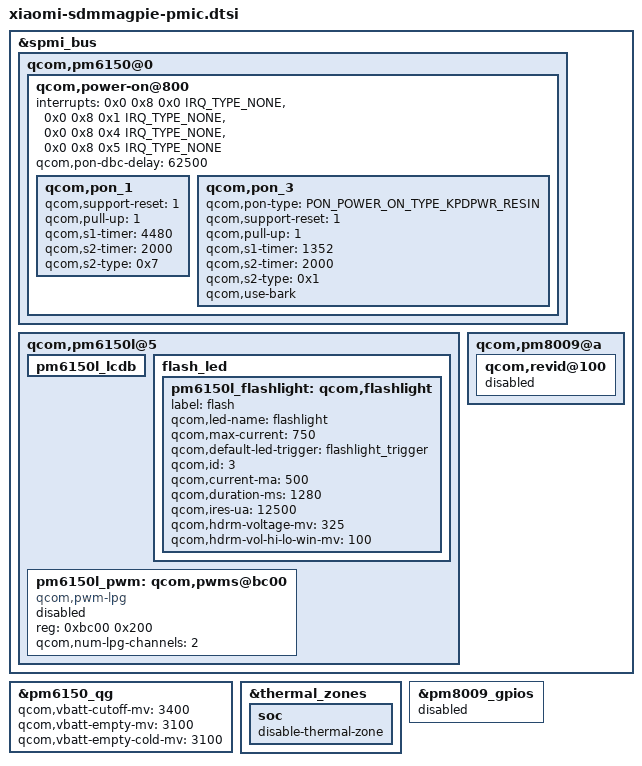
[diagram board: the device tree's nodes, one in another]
/*
 * Copyright (C) 2020 The LineageOS Project
 *
 */

#include <dt-bindings/input/input.h>
#include <dt-bindings/input/qcom,qpnp-power-on.h>
#include <dt-bindings/interrupt-controller/irq.h>
#include <dt-bindings/spmi/spmi.h>
#include <dt-bindings/iio/qcom,spmi-vadc.h>

&spmi_bus {
    qcom,pm6150@0 {
        qcom,power-on@800 {
            interrupts = <0x0 0x8 0x0 IRQ_TYPE_NONE>,
                   <0x0 0x8 0x1 IRQ_TYPE_NONE>,
                   <0x0 0x8 0x4 IRQ_TYPE_NONE>,
                   <0x0 0x8 0x5 IRQ_TYPE_NONE>;
            interrupt-names = "kpdpwr", "resin",
                    "resin-bark", "kpdpwr-resin-bark";
            qcom,pon-dbc-delay = <62500>;
            qcom,pon_1 {
                qcom,support-reset = <1>;
                qcom,pull-up = <1>;
                qcom,s1-timer = <4480>;
                qcom,s2-timer = <2000>;
                qcom,s2-type = <0x7>;
            };
            qcom,pon_3 {
                qcom,pon-type = <PON_POWER_ON_TYPE_KPDPWR_RESIN>;
                qcom,support-reset = <1>;
                qcom,pull-up = <1>;
                qcom,s1-timer = <1352>;
                qcom,s2-timer = <2000>;
                qcom,s2-type = <0x1>;
                qcom,use-bark;
            };
        };
    };
    qcom,pm6150l@5 {
        /delete-node/ pm6150l_pwm_1;
        pm6150l_lcdb {
            /delete-property/ qcom,voltage-step-ramp;
        };
        flash_led {
            pm6150l_flashlight: qcom,flashlight {
                label = "flash";
                qcom,led-name = "flashlight";
                qcom,max-current = <750>;
                qcom,default-led-trigger = "flashlight_trigger";
                qcom,id = <3>;
                qcom,current-ma = <500>;
                qcom,duration-ms = <1280>;
                qcom,ires-ua = <12500>;
                qcom,hdrm-voltage-mv = <325>;
                qcom,hdrm-vol-hi-lo-win-mv = <100>;
            };
        };
        pm6150l_pwm: qcom,pwms@bc00 {
            compatible = "qcom,pwm-lpg";
            reg = <0xbc00 0x200>;
            reg-names = "lpg-base";
            #pwm-cells = <2>;
            qcom,num-lpg-channels = <2>;
            status = "disabled";
        };
    };
    qcom,pm8009@a {
        qcom,revid@100 {
            status = "disabled";
        };
    };
};

&pm6150_qg {
        qcom,vbatt-cutoff-mv = <3400>;
        qcom,vbatt-empty-mv = <3100>;
        qcom,vbatt-empty-cold-mv = <3100>;
};

&thermal_zones {
    soc {
        disable-thermal-zone;
    };
};

&pm8009_gpios {
    status = "disabled";
};
